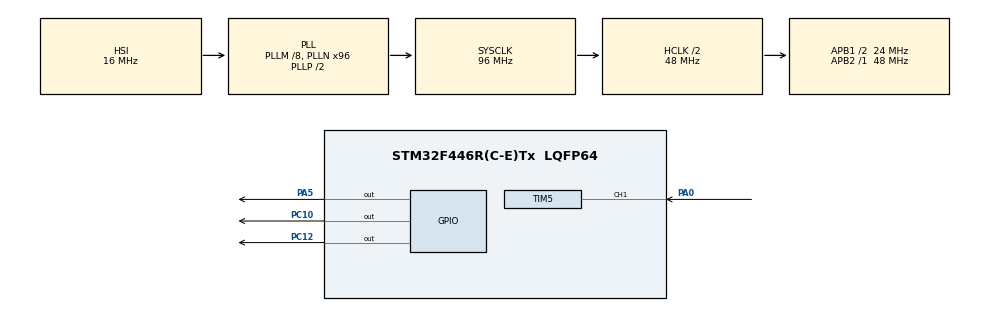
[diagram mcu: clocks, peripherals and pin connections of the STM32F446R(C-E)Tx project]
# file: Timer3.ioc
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Mcu.Family=STM32F4
Mcu.Name=STM32F446R(C-E)Tx
Mcu.Package=LQFP64
NVIC.PriorityGroup=NVIC_PRIORITYGROUP_4
NVIC.TIM5_IRQn=true\:0\:0\:false\:false\:true\:true\:true
PA0-WKUP.Signal=S_TIM5_CH1
PA5.GPIO_Speed=GPIO_SPEED_FREQ_MEDIUM
PA5.Signal=GPIO_Output
PC10.GPIO_Speed=GPIO_SPEED_FREQ_MEDIUM
PC10.PinState=GPIO_PIN_RESET
PC10.Signal=GPIO_Output
PC12.GPIO_Speed=GPIO_SPEED_FREQ_MEDIUM
PC12.Signal=GPIO_Output
ProjectManager.HeapSize=0x200
ProjectManager.StackSize=0x400
ProjectManager.TargetToolchain=MDK-ARM V5.27
RCC.AHBCLKDivider=RCC_SYSCLK_DIV2
RCC.AHBFreq_Value=48000000
RCC.APB1CLKDivider=RCC_HCLK_DIV2
RCC.APB1Freq_Value=24000000
RCC.APB1TimFreq_Value=48000000
RCC.APB2Freq_Value=48000000
RCC.APB2TimFreq_Value=48000000
RCC.CortexFreq_Value=48000000
RCC.HCLKFreq_Value=48000000
RCC.PLLM=8
RCC.PLLN=96
RCC.SYSCLKFreq_VALUE=96000000
RCC.SYSCLKSource=RCC_SYSCLKSOURCE_PLLCLK
RCC.USBFreq_Value=96000000
RCC.VCOOutputFreq_Value=192000000
SH.S_TIM5_CH1.0=TIM5_CH1,TriggerSource_TI1FP1
TIM5.Period=10000
TIM5.Prescaler=47999
TIM5.Slave_TriggerFilter=15
VP_TIM5_VS_ControllerModeGated.Mode=Gated Mode
board=custom

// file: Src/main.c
/* USER CODE BEGIN Header */
/**
  ******************************************************************************
  * @file           : main.c
  * @brief          : Main program body
  ******************************************************************************
  * @attention
  *
  * <h2><center>&copy; Copyright (c) 2020 STMicroelectronics.
  * All rights reserved.</center></h2>
  *
  * This software component is licensed by ST under BSD 3-Clause license,
  * the "License"; You may not use this file except in compliance with the
  * License. You may obtain a copy of the License at:
  *                        opensource.org/licenses/BSD-3-Clause
  *
  ******************************************************************************
  */
/* USER CODE END Header */

#include "main.h"

TIM_HandleTypeDef htim5;

/* USER CODE BEGIN PV */
uint32_t sayac = 0, sayac1=0;
/* USER CODE END PV */

void SystemClock_Config(void);
static void MX_GPIO_Init(void);
static void MX_TIM5_Init(void);

int main(void)
{

  /* MCU Configuration--------------------------------------------------------*/

  /* Reset of all peripherals, Initializes the Flash interface and the Systick. */
  HAL_Init();

  /* Configure the system clock */
  SystemClock_Config();

  /* Initialize all configured peripherals */
  MX_GPIO_Init();
  MX_TIM5_Init();
  /* USER CODE BEGIN 2 */
	HAL_TIM_Base_Start_IT(&htim5);
  /* USER CODE END 2 */

  /* Infinite loop */
  while (1)
  {

    /* USER CODE BEGIN 3 */
		sayac = __HAL_TIM_GetCounter(&htim5);
		while(__HAL_TIM_GET_FLAG(&htim5,TIM_FLAG_TRIGGER) != RESET)
	{
		HAL_GPIO_TogglePin(GPIOC,GPIO_PIN_12);
		__HAL_TIM_CLEAR_FLAG(&htim5,TIM_FLAG_TRIGGER);
	}

	}

  /* USER CODE END 3 */
}

void SystemClock_Config(void)
{
  RCC_OscInitTypeDef RCC_OscInitStruct = {0};
  RCC_ClkInitTypeDef RCC_ClkInitStruct = {0};

  /** Configure the main internal regulator output voltage
  */
  __HAL_RCC_PWR_CLK_ENABLE();
  __HAL_PWR_VOLTAGESCALING_CONFIG(PWR_REGULATOR_VOLTAGE_SCALE3);
  /** Initializes the CPU, AHB and APB busses clocks
  */
  RCC_OscInitStruct.OscillatorType = RCC_OSCILLATORTYPE_HSI;
  RCC_OscInitStruct.HSIState = RCC_HSI_ON;
  RCC_OscInitStruct.HSICalibrationValue = RCC_HSICALIBRATION_DEFAULT;
  RCC_OscInitStruct.PLL.PLLState = RCC_PLL_ON;
  RCC_OscInitStruct.PLL.PLLSource = RCC_PLLSOURCE_HSI;
  RCC_OscInitStruct.PLL.PLLM = 8;
  RCC_OscInitStruct.PLL.PLLN = 96;
  RCC_OscInitStruct.PLL.PLLP = RCC_PLLP_DIV2;
  RCC_OscInitStruct.PLL.PLLQ = 2;
  RCC_OscInitStruct.PLL.PLLR = 2;
  if (HAL_RCC_OscConfig(&RCC_OscInitStruct) != HAL_OK)
  {
    Error_Handler();
  }
  /** Initializes the CPU, AHB and APB busses clocks
  */
  RCC_ClkInitStruct.ClockType = RCC_CLOCKTYPE_HCLK|RCC_CLOCKTYPE_SYSCLK
                              |RCC_CLOCKTYPE_PCLK1|RCC_CLOCKTYPE_PCLK2;
  RCC_ClkInitStruct.SYSCLKSource = RCC_SYSCLKSOURCE_PLLCLK;
  RCC_ClkInitStruct.AHBCLKDivider = RCC_SYSCLK_DIV2;
  RCC_ClkInitStruct.APB1CLKDivider = RCC_HCLK_DIV2;
  RCC_ClkInitStruct.APB2CLKDivider = RCC_HCLK_DIV1;

  if (HAL_RCC_ClockConfig(&RCC_ClkInitStruct, FLASH_LATENCY_1) != HAL_OK)
  {
    Error_Handler();
  }
}

static void MX_TIM5_Init(void)
{

  TIM_SlaveConfigTypeDef sSlaveConfig = {0};
  TIM_MasterConfigTypeDef sMasterConfig = {0};

  htim5.Instance = TIM5;
  htim5.Init.Prescaler = 47999;
  htim5.Init.CounterMode = TIM_COUNTERMODE_UP;
  htim5.Init.Period = 10000;
  htim5.Init.ClockDivision = TIM_CLOCKDIVISION_DIV1;
  htim5.Init.AutoReloadPreload = TIM_AUTORELOAD_PRELOAD_DISABLE;
  if (HAL_TIM_Base_Init(&htim5) != HAL_OK)
  {
    Error_Handler();
  }
  sSlaveConfig.SlaveMode = TIM_SLAVEMODE_GATED;
  sSlaveConfig.InputTrigger = TIM_TS_TI1FP1;
  sSlaveConfig.TriggerPolarity = TIM_TRIGGERPOLARITY_RISING;
  sSlaveConfig.TriggerFilter = 15;
  if (HAL_TIM_SlaveConfigSynchro(&htim5, &sSlaveConfig) != HAL_OK)
  {
    Error_Handler();
  }
  sMasterConfig.MasterOutputTrigger = TIM_TRGO_RESET;
  sMasterConfig.MasterSlaveMode = TIM_MASTERSLAVEMODE_DISABLE;
  if (HAL_TIMEx_MasterConfigSynchronization(&htim5, &sMasterConfig) != HAL_OK)
  {
    Error_Handler();
  }

}

static void MX_GPIO_Init(void)
{
  GPIO_InitTypeDef GPIO_InitStruct = {0};

  /* GPIO Ports Clock Enable */
  __HAL_RCC_GPIOA_CLK_ENABLE();
  __HAL_RCC_GPIOC_CLK_ENABLE();

  /*Configure GPIO pin Output Level */
  HAL_GPIO_WritePin(GPIOA, GPIO_PIN_5, GPIO_PIN_RESET);

  /*Configure GPIO pin Output Level */
  HAL_GPIO_WritePin(GPIOC, GPIO_PIN_10|GPIO_PIN_12, GPIO_PIN_RESET);

  /*Configure GPIO pin : PA5 */
  GPIO_InitStruct.Pin = GPIO_PIN_5;
  GPIO_InitStruct.Mode = GPIO_MODE_OUTPUT_PP;
  GPIO_InitStruct.Pull = GPIO_NOPULL;
  GPIO_InitStruct.Speed = GPIO_SPEED_FREQ_MEDIUM;
  HAL_GPIO_Init(GPIOA, &GPIO_InitStruct);

  /*Configure GPIO pins : PC10 PC12 */
  GPIO_InitStruct.Pin = GPIO_PIN_10|GPIO_PIN_12;
  GPIO_InitStruct.Mode = GPIO_MODE_OUTPUT_PP;
  GPIO_InitStruct.Pull = GPIO_NOPULL;
  GPIO_InitStruct.Speed = GPIO_SPEED_FREQ_MEDIUM;
  HAL_GPIO_Init(GPIOC, &GPIO_InitStruct);

}

void Error_Handler(void)
{
}

/************************ (C) COPYRIGHT STMicroelectronics *****END OF FILE****/
